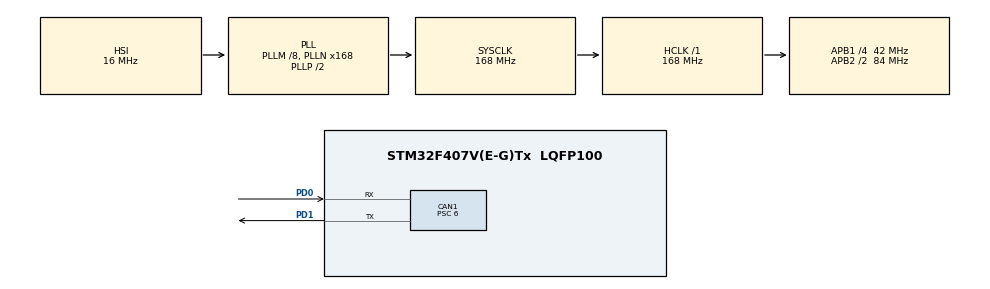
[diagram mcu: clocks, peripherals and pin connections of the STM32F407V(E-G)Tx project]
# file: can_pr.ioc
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CAN1.BS1=CAN_BS1_4TQ
CAN1.BS2=CAN_BS2_2TQ
CAN1.CalculateBaudRate=1000000
CAN1.CalculateTimeBit=1000
CAN1.CalculateTimeQuantum=142.85714285714286
CAN1.Prescaler=6
Mcu.Family=STM32F4
Mcu.Name=STM32F407V(E-G)Tx
Mcu.Package=LQFP100
NVIC.CAN1_RX0_IRQn=true\:0\:0\:false\:false\:true\:true\:true\:true
NVIC.CAN1_RX1_IRQn=true\:0\:0\:false\:false\:true\:true\:true\:true
NVIC.CAN1_SCE_IRQn=true\:0\:0\:false\:false\:true\:true\:true\:true
NVIC.PriorityGroup=NVIC_PRIORITYGROUP_0
PD0.Mode=CAN_Activate
PD0.Signal=CAN1_RX
PD1.Mode=CAN_Activate
PD1.Signal=CAN1_TX
ProjectManager.HeapSize=0x200
ProjectManager.StackSize=0x400
ProjectManager.TargetToolchain=STM32CubeIDE
RCC.48MHZClocksFreq_Value=48000000
RCC.AHBFreq_Value=168000000
RCC.APB1CLKDivider=RCC_HCLK_DIV4
RCC.APB1Freq_Value=42000000
RCC.APB1TimFreq_Value=84000000
RCC.APB2CLKDivider=RCC_HCLK_DIV2
RCC.APB2Freq_Value=84000000
RCC.APB2TimFreq_Value=168000000
RCC.CortexFreq_Value=168000000
RCC.HCLKFreq_Value=168000000
RCC.HSE_VALUE=8000000
RCC.HSI_VALUE=16000000
RCC.LSE_VALUE=32768
RCC.PLLM=8
RCC.PLLN=168
RCC.PLLQ=7
RCC.SYSCLKFreq_VALUE=168000000
RCC.SYSCLKSource=RCC_SYSCLKSOURCE_PLLCLK
RCC.VCOOutputFreq_Value=336000000
VP_TIM6_VS_ClockSourceINT.Mode=Enable_Timer
board=STM32F407G-DISC1

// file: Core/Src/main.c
/* USER CODE BEGIN Header */
/**
  ******************************************************************************
  * @file           : main.c
  * @brief          : Main program body
  ******************************************************************************
  * @attention
  *
  * Copyright (c) 2023 STMicroelectronics.
  * All rights reserved.
  *
  * This software is licensed under terms that can be found in the LICENSE file
  * in the root directory of this software component.
  * If no LICENSE file comes with this software, it is provided AS-IS.
  *
  ******************************************************************************
  */
/* USER CODE END Header */
#include "main.h"

CAN_HandleTypeDef hcan1;

TIM_HandleTypeDef htim6;

void SystemClock_Config(void);
static void MX_GPIO_Init(void);
static void MX_CAN1_Init(void);
static void MX_TIM6_Init(void);

int main(void)
{
  /* USER CODE BEGIN 1 */
	uint8_t aData[8];
	aData[0]=0x02;
	aData[1]=0X3E;
	aData[2]=0x02;
	aData[3]=0X3E;
	aData[4]=0x02;
	aData[5]=0X3E;
	aData[6]=0x02;
	aData[7]=0X3E;

	CAN_TxHeaderTypeDef tester_present;
	tester_present.DLC=0x02;
	tester_present.ExtId=0x00;
	tester_present.IDE=0x00;
	tester_present.RTR=0x00;
	tester_present.StdId=0x7df;
	tester_present.TransmitGlobalTime=RESET;

  /* USER CODE END 1 */

  /* MCU Configuration--------------------------------------------------------*/

  /* Reset of all peripherals, Initializes the Flash interface and the Systick. */
  HAL_Init();

  /* Configure the system clock */
  SystemClock_Config();

  /* Initialize all configured peripherals */
  MX_GPIO_Init();
  MX_CAN1_Init();
  MX_TIM6_Init();
  /* USER CODE BEGIN 2 */
  HAL_CAN_Start(&hcan1);

  /* USER CODE END 2 */

  /* Infinite loop */
  while (1)
  {

    /* USER CODE BEGIN 3 */
	  HAL_CAN_AddTxMessage(&hcan1,&tester_present,aData,NULL);
	  HAL_Delay(500);
	  aData[0]++;

  }
  /* USER CODE END 3 */
}

void SystemClock_Config(void)
{
  RCC_OscInitTypeDef RCC_OscInitStruct = {0};
  RCC_ClkInitTypeDef RCC_ClkInitStruct = {0};

  /** Configure the main internal regulator output voltage
  */
  __HAL_RCC_PWR_CLK_ENABLE();
  __HAL_PWR_VOLTAGESCALING_CONFIG(PWR_REGULATOR_VOLTAGE_SCALE1);

  /** Initializes the RCC Oscillators according to the specified parameters
  * in the RCC_OscInitTypeDef structure.
  */
  RCC_OscInitStruct.OscillatorType = RCC_OSCILLATORTYPE_HSI;
  RCC_OscInitStruct.HSIState = RCC_HSI_ON;
  RCC_OscInitStruct.HSICalibrationValue = RCC_HSICALIBRATION_DEFAULT;
  RCC_OscInitStruct.PLL.PLLState = RCC_PLL_ON;
  RCC_OscInitStruct.PLL.PLLSource = RCC_PLLSOURCE_HSI;
  RCC_OscInitStruct.PLL.PLLM = 8;
  RCC_OscInitStruct.PLL.PLLN = 168;
  RCC_OscInitStruct.PLL.PLLP = RCC_PLLP_DIV2;
  RCC_OscInitStruct.PLL.PLLQ = 7;
  if (HAL_RCC_OscConfig(&RCC_OscInitStruct) != HAL_OK)
  {
    Error_Handler();
  }

  /** Initializes the CPU, AHB and APB buses clocks
  */
  RCC_ClkInitStruct.ClockType = RCC_CLOCKTYPE_HCLK|RCC_CLOCKTYPE_SYSCLK
                              |RCC_CLOCKTYPE_PCLK1|RCC_CLOCKTYPE_PCLK2;
  RCC_ClkInitStruct.SYSCLKSource = RCC_SYSCLKSOURCE_PLLCLK;
  RCC_ClkInitStruct.AHBCLKDivider = RCC_SYSCLK_DIV1;
  RCC_ClkInitStruct.APB1CLKDivider = RCC_HCLK_DIV4;
  RCC_ClkInitStruct.APB2CLKDivider = RCC_HCLK_DIV2;

  if (HAL_RCC_ClockConfig(&RCC_ClkInitStruct, FLASH_LATENCY_5) != HAL_OK)
  {
    Error_Handler();
  }
}

static void MX_CAN1_Init(void)
{

  hcan1.Instance = CAN1;
  hcan1.Init.Prescaler = 6;
  hcan1.Init.Mode = CAN_MODE_NORMAL;
  hcan1.Init.SyncJumpWidth = CAN_SJW_1TQ;
  hcan1.Init.TimeSeg1 = CAN_BS1_4TQ;
  hcan1.Init.TimeSeg2 = CAN_BS2_2TQ;
  hcan1.Init.TimeTriggeredMode = DISABLE;
  hcan1.Init.AutoBusOff = DISABLE;
  hcan1.Init.AutoWakeUp = DISABLE;
  hcan1.Init.AutoRetransmission = DISABLE;
  hcan1.Init.ReceiveFifoLocked = DISABLE;
  hcan1.Init.TransmitFifoPriority = DISABLE;
  if (HAL_CAN_Init(&hcan1) != HAL_OK)
  {
    Error_Handler();
  }

}

static void MX_TIM6_Init(void)
{

  TIM_MasterConfigTypeDef sMasterConfig = {0};

  htim6.Instance = TIM6;
  htim6.Init.Prescaler = 0;
  htim6.Init.CounterMode = TIM_COUNTERMODE_UP;
  htim6.Init.Period = 65535;
  htim6.Init.AutoReloadPreload = TIM_AUTORELOAD_PRELOAD_DISABLE;
  if (HAL_TIM_Base_Init(&htim6) != HAL_OK)
  {
    Error_Handler();
  }
  sMasterConfig.MasterOutputTrigger = TIM_TRGO_RESET;
  sMasterConfig.MasterSlaveMode = TIM_MASTERSLAVEMODE_DISABLE;
  if (HAL_TIMEx_MasterConfigSynchronization(&htim6, &sMasterConfig) != HAL_OK)
  {
    Error_Handler();
  }

}

static void MX_GPIO_Init(void)
{

  /* GPIO Ports Clock Enable */
  __HAL_RCC_GPIOD_CLK_ENABLE();

}

void Error_Handler(void)
{
  __disable_irq();
  while (1)
  {
  }
}
